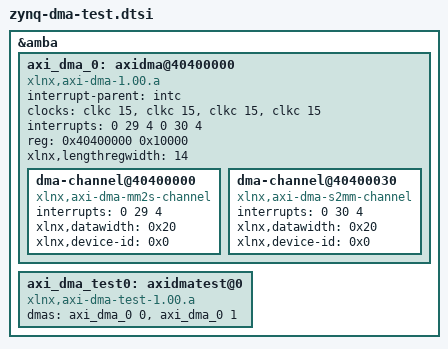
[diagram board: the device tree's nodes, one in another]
&amba {

	axi_dma_0: axidma@40400000 {
		interrupt-parent = <&intc>;
		compatible = "xlnx,axi-dma-1.00.a";
		#dma-cells = <1>;
		clock-names = "s_axi_lite_aclk", "m_axi_sg_aclk", "m_axi_mm2s_aclk", "m_axi_s2mm_aclk";
                clocks = <&clkc 15>, <&clkc 15>, <&clkc 15>, <&clkc 15>;
		interrupts = < 0 29 4 0 30 4>;
		reg = < 0x40400000 0x10000 >;
		xlnx,lengthregwidth = <14>;
		dma-channel@40400000 {
			compatible = "xlnx,axi-dma-mm2s-channel";
			interrupts = < 0 29 4 >;
			xlnx,datawidth = <0x20>;
			xlnx,device-id = <0x0>;

		} ;
		dma-channel@40400030 {
			compatible = "xlnx,axi-dma-s2mm-channel";
			interrupts = < 0 30 4 >;
			xlnx,datawidth = <0x20>;
			xlnx,device-id = <0x0>;

		} ;
	};

	axi_dma_test0: axidmatest@0 {
		compatible = "xlnx,axi-dma-test-1.00.a";
		dmas = <&axi_dma_0 0 &axi_dma_0 1>;
		dma-names = "axidma0", "axidma1";
	};
};
